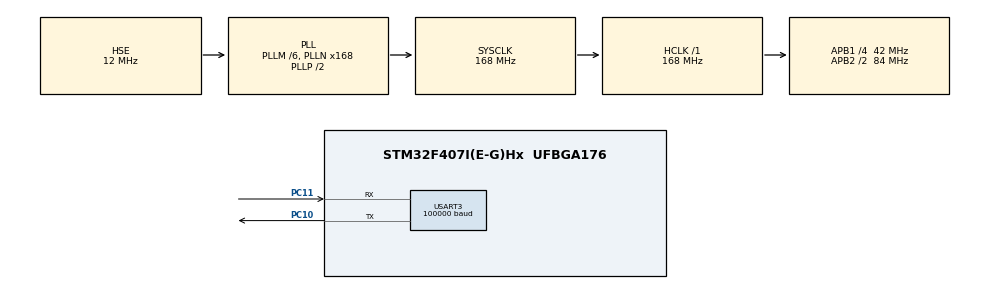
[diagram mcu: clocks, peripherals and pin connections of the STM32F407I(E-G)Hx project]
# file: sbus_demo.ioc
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Dma.Request0=USART3_RX
Dma.USART3_RX.0.Direction=DMA_PERIPH_TO_MEMORY
Dma.USART3_RX.0.FIFOMode=DMA_FIFOMODE_DISABLE
Dma.USART3_RX.0.Instance=DMA1_Stream1
Dma.USART3_RX.0.MemDataAlignment=DMA_MDATAALIGN_BYTE
Dma.USART3_RX.0.MemInc=DMA_MINC_ENABLE
Dma.USART3_RX.0.Mode=DMA_NORMAL
Dma.USART3_RX.0.PeriphDataAlignment=DMA_PDATAALIGN_BYTE
Dma.USART3_RX.0.PeriphInc=DMA_PINC_DISABLE
Dma.USART3_RX.0.Priority=DMA_PRIORITY_VERY_HIGH
Mcu.Family=STM32F4
Mcu.Name=STM32F407I(E-G)Hx
Mcu.Package=UFBGA176
NVIC.DMA1_Stream1_IRQn=true\:0\:0\:false\:false\:true\:false\:true\:true
NVIC.PriorityGroup=NVIC_PRIORITYGROUP_4
NVIC.USART3_IRQn=true\:0\:0\:false\:false\:false\:true\:true\:true
PA13.Mode=Serial_Wire
PA13.Signal=SYS_JTMS-SWDIO
PA14.Mode=Serial_Wire
PA14.Signal=SYS_JTCK-SWCLK
PC10.Mode=Asynchronous
PC10.Signal=USART3_TX
PC11.Mode=Asynchronous
PC11.Signal=USART3_RX
PH0-OSC_IN.Mode=HSE-External-Oscillator
PH0-OSC_IN.Signal=RCC_OSC_IN
PH1-OSC_OUT.Mode=HSE-External-Oscillator
PH1-OSC_OUT.Signal=RCC_OSC_OUT
ProjectManager.HeapSize=0x200
ProjectManager.StackSize=0x400
ProjectManager.TargetToolchain=MDK-ARM V5.32
RCC.48MHZClocksFreq_Value=84000000
RCC.AHBFreq_Value=168000000
RCC.APB1CLKDivider=RCC_HCLK_DIV4
RCC.APB1Freq_Value=42000000
RCC.APB1TimFreq_Value=84000000
RCC.APB2CLKDivider=RCC_HCLK_DIV2
RCC.APB2Freq_Value=84000000
RCC.APB2TimFreq_Value=168000000
RCC.CortexFreq_Value=168000000
RCC.HCLKFreq_Value=168000000
RCC.HSE_VALUE=12000000
RCC.HSI_VALUE=16000000
RCC.LSE_VALUE=32768
RCC.PLLM=6
RCC.PLLN=168
RCC.PLLSourceVirtual=RCC_PLLSOURCE_HSE
RCC.SYSCLKFreq_VALUE=168000000
RCC.SYSCLKSource=RCC_SYSCLKSOURCE_PLLCLK
RCC.VCOOutputFreq_Value=336000000
USART3.BaudRate=100000
USART3.Parity=PARITY_NONE
USART3.VirtualMode=VM_ASYNC
board=custom

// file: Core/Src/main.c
/* USER CODE BEGIN Header */
/**
  ******************************************************************************
  * @file           : main.c
  * @brief          : Main program body
  ******************************************************************************
  * @attention
  *
  * Copyright (c) 2023 STMicroelectronics.
  * All rights reserved.
  *
  * This software is licensed under terms that can be found in the LICENSE file
  * in the root directory of this software component.
  * If no LICENSE file comes with this software, it is provided AS-IS.
  *
  ******************************************************************************
  */
/* USER CODE END Header */
#include "main.h"

/* USER CODE BEGIN Includes */
#include "bsp_rc.h"
#include "remote_control.h"
/* USER CODE END Includes */

UART_HandleTypeDef huart3;
DMA_HandleTypeDef hdma_usart3_rx;

void SystemClock_Config(void);
static void MX_GPIO_Init(void);
static void MX_DMA_Init(void);
static void MX_USART3_UART_Init(void);

/* USER CODE BEGIN 0 */
test_control_data_t test_control_data; // 遥控器测试全局数据，test_control_data_t在main.h

/* USER CODE END 0 */

int main(void)
{

  /* MCU Configuration--------------------------------------------------------*/

  /* Reset of all peripherals, Initializes the Flash interface and the Systick. */
  HAL_Init();

  /* Configure the system clock */
  SystemClock_Config();

  /* Initialize all configured peripherals */
  MX_GPIO_Init();
  MX_DMA_Init();
  MX_USART3_UART_Init();
  /* USER CODE BEGIN 2 */
    remote_control_init();//遥控器初始化
    test_control_data.test_rc = get_remote_control_point();//遥控器数据绑定
  /* USER CODE END 2 */

  /* Infinite loop */
  while (1)
  {

  }
}

void SystemClock_Config(void)
{
  RCC_OscInitTypeDef RCC_OscInitStruct = {0};
  RCC_ClkInitTypeDef RCC_ClkInitStruct = {0};

  /** Configure the main internal regulator output voltage
  */
  __HAL_RCC_PWR_CLK_ENABLE();
  __HAL_PWR_VOLTAGESCALING_CONFIG(PWR_REGULATOR_VOLTAGE_SCALE1);

  /** Initializes the RCC Oscillators according to the specified parameters
  * in the RCC_OscInitTypeDef structure.
  */
  RCC_OscInitStruct.OscillatorType = RCC_OSCILLATORTYPE_HSE;
  RCC_OscInitStruct.HSEState = RCC_HSE_ON;
  RCC_OscInitStruct.PLL.PLLState = RCC_PLL_ON;
  RCC_OscInitStruct.PLL.PLLSource = RCC_PLLSOURCE_HSE;
  RCC_OscInitStruct.PLL.PLLM = 6;
  RCC_OscInitStruct.PLL.PLLN = 168;
  RCC_OscInitStruct.PLL.PLLP = RCC_PLLP_DIV2;
  RCC_OscInitStruct.PLL.PLLQ = 4;
  if (HAL_RCC_OscConfig(&RCC_OscInitStruct) != HAL_OK)
  {
    Error_Handler();
  }

  /** Initializes the CPU, AHB and APB buses clocks
  */
  RCC_ClkInitStruct.ClockType = RCC_CLOCKTYPE_HCLK|RCC_CLOCKTYPE_SYSCLK
                              |RCC_CLOCKTYPE_PCLK1|RCC_CLOCKTYPE_PCLK2;
  RCC_ClkInitStruct.SYSCLKSource = RCC_SYSCLKSOURCE_PLLCLK;
  RCC_ClkInitStruct.AHBCLKDivider = RCC_SYSCLK_DIV1;
  RCC_ClkInitStruct.APB1CLKDivider = RCC_HCLK_DIV4;
  RCC_ClkInitStruct.APB2CLKDivider = RCC_HCLK_DIV2;

  if (HAL_RCC_ClockConfig(&RCC_ClkInitStruct, FLASH_LATENCY_5) != HAL_OK)
  {
    Error_Handler();
  }
}

static void MX_USART3_UART_Init(void)
{

  huart3.Instance = USART3;
  huart3.Init.BaudRate = 100000;
  huart3.Init.WordLength = UART_WORDLENGTH_8B;
  huart3.Init.StopBits = UART_STOPBITS_1;
  huart3.Init.Parity = UART_PARITY_NONE;
  huart3.Init.Mode = UART_MODE_TX_RX;
  huart3.Init.HwFlowCtl = UART_HWCONTROL_NONE;
  huart3.Init.OverSampling = UART_OVERSAMPLING_16;
  if (HAL_UART_Init(&huart3) != HAL_OK)
  {
    Error_Handler();
  }

}

static void MX_DMA_Init(void)
{

  /* DMA controller clock enable */
  __HAL_RCC_DMA1_CLK_ENABLE();

  /* DMA interrupt init */
  /* DMA1_Stream1_IRQn interrupt configuration */
  HAL_NVIC_SetPriority(DMA1_Stream1_IRQn, 0, 0);
  HAL_NVIC_EnableIRQ(DMA1_Stream1_IRQn);

}

static void MX_GPIO_Init(void)
{

  /* GPIO Ports Clock Enable */
  __HAL_RCC_GPIOA_CLK_ENABLE();
  __HAL_RCC_GPIOC_CLK_ENABLE();
  __HAL_RCC_GPIOH_CLK_ENABLE();

}

void Error_Handler(void)
{
  __disable_irq();
  while (1)
  {
  }
}
